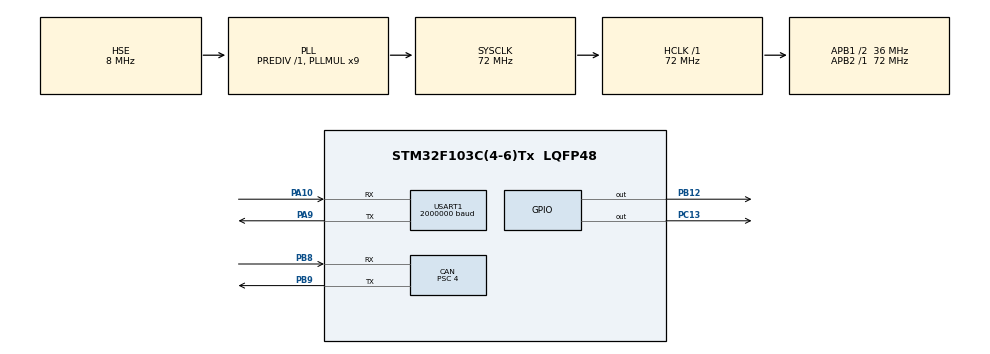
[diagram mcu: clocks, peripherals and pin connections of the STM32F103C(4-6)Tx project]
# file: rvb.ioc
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CAN.ABOM=ENABLE
CAN.AWUM=ENABLE
CAN.BS1=CAN_BS1_9TQ
CAN.BS2=CAN_BS2_8TQ
CAN.CalculateBaudRate=500000
CAN.CalculateTimeBit=2000
CAN.CalculateTimeQuantum=111.11111111111111
CAN.Mode=CAN_MODE_NORMAL
CAN.NART=DISABLE
CAN.Prescaler=4
CAN.RFLM=DISABLE
CAN.SJW=CAN_SJW_4TQ
CAN.TTCM=ENABLE
CAN.TXFP=DISABLE
FREERTOS.Queues01=QueueIO,8,sMessageType,0,Dynamic,NULL,NULL;QueueAppCAN,16,sMessageType,0,Dynamic,NULL,NULL;QueueAppSerial,16,sMessageType,0,Dynamic,NULL,NULL
FREERTOS.Tasks01=TaskIO,-3,128,TaskIO_Init,Default,NULL,Dynamic,NULL,NULL;TaskAppCAN,-3,128,TaskAppCAN_Init,Default,NULL,Dynamic,NULL,NULL;TaskAppSerial,-3,128,TaskAppSerial_Init,Default,NULL,Dynamic,NULL,NULL
FREERTOS.Timers01=TimerIO,vTimerCallbackIo,osTimerPeriodic,Default,NULL,Dynamic,NULL
FREERTOS.configUSE_NEWLIB_REENTRANT=1
FREERTOS.configUSE_TIMERS=1
FREERTOS.copyHeapFile=0
Mcu.Family=STM32F1
Mcu.Name=STM32F103C(4-6)Tx
Mcu.Package=LQFP48
NVIC.PriorityGroup=NVIC_PRIORITYGROUP_4
PA10.Mode=Asynchronous
PA10.Signal=USART1_RX
PA13.Mode=Serial_Wire
PA13.Signal=SYS_JTMS-SWDIO
PA14.Mode=Serial_Wire
PA14.Signal=SYS_JTCK-SWCLK
PA9.Mode=Asynchronous
PA9.Signal=USART1_TX
PB12.Signal=GPIO_Output
PB8.GPIO_Mode=GPIO_MODE_INPUT
PB8.GPIO_PuPd=GPIO_NOPULL
PB8.Mode=CAN_Activate
PB8.Signal=CAN_RX
PB9.Mode=CAN_Activate
PB9.Signal=CAN_TX
PC13-TAMPER-RTC.Signal=GPIO_Output
PD0-OSC_IN.Mode=HSE-External-Oscillator
PD0-OSC_IN.Signal=RCC_OSC_IN
PD1-OSC_OUT.Mode=HSE-External-Oscillator
PD1-OSC_OUT.Signal=RCC_OSC_OUT
ProjectManager.HeapSize=0x200
ProjectManager.StackSize=0x400
ProjectManager.TargetToolchain=STM32CubeIDE
RCC.AHBFreq_Value=72000000
RCC.APB1CLKDivider=RCC_HCLK_DIV2
RCC.APB1Freq_Value=36000000
RCC.APB1TimFreq_Value=72000000
RCC.APB2Freq_Value=72000000
RCC.APB2TimFreq_Value=72000000
RCC.HCLKFreq_Value=72000000
RCC.PLLMUL=RCC_PLL_MUL9
RCC.PLLSourceVirtual=RCC_PLLSOURCE_HSE
RCC.SYSCLKFreq_VALUE=72000000
RCC.SYSCLKSource=RCC_SYSCLKSOURCE_PLLCLK
RCC.USBFreq_Value=72000000
USART1.BaudRate=2000000
USART1.VirtualMode=VM_ASYNC
VP_FREERTOS_VS_CMSIS_V1.Mode=CMSIS_V1
board=custom

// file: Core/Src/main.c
/* USER CODE BEGIN Header */
/**
  ******************************************************************************
  * @file           : main.c
  * @brief          : Main program body
  ******************************************************************************
  * @attention
  *
  * Copyright (c) 2024 STMicroelectronics.
  * All rights reserved.
  *
  * This software is licensed under terms that can be found in the LICENSE file
  * in the root directory of this software component.
  * If no LICENSE file comes with this software, it is provided AS-IS.
  *
  ******************************************************************************
  */
/* USER CODE END Header */
#include "main.h"
#include "cmsis_os.h"
#include "can.h"
#include "usart.h"
#include "gpio.h"

void SystemClock_Config(void);
void MX_FREERTOS_Init(void);

int main(void)
{

  /* MCU Configuration--------------------------------------------------------*/

  /* Reset of all peripherals, Initializes the Flash interface and the Systick. */
  HAL_Init();

  /* Configure the system clock */
  SystemClock_Config();

  /* Initialize all configured peripherals */
  MX_GPIO_Init();
  MX_CAN_Init();
  MX_USART1_UART_Init();

  /* Call init function for freertos objects (in cmsis_os2.c) */
  MX_FREERTOS_Init();

  /* Start scheduler */
  osKernelStart();

  /* We should never get here as control is now taken by the scheduler */

  /* Infinite loop */
  while (1)
  {

  }
}

void SystemClock_Config(void)
{
  RCC_OscInitTypeDef RCC_OscInitStruct = {0};
  RCC_ClkInitTypeDef RCC_ClkInitStruct = {0};

  /** Initializes the RCC Oscillators according to the specified parameters
  * in the RCC_OscInitTypeDef structure.
  */
  RCC_OscInitStruct.OscillatorType = RCC_OSCILLATORTYPE_HSE;
  RCC_OscInitStruct.HSEState = RCC_HSE_ON;
  RCC_OscInitStruct.HSEPredivValue = RCC_HSE_PREDIV_DIV1;
  RCC_OscInitStruct.HSIState = RCC_HSI_ON;
  RCC_OscInitStruct.PLL.PLLState = RCC_PLL_ON;
  RCC_OscInitStruct.PLL.PLLSource = RCC_PLLSOURCE_HSE;
  RCC_OscInitStruct.PLL.PLLMUL = RCC_PLL_MUL9;
  if (HAL_RCC_OscConfig(&RCC_OscInitStruct) != HAL_OK)
  {
    Error_Handler();
  }

  /** Initializes the CPU, AHB and APB buses clocks
  */
  RCC_ClkInitStruct.ClockType = RCC_CLOCKTYPE_HCLK|RCC_CLOCKTYPE_SYSCLK
                              |RCC_CLOCKTYPE_PCLK1|RCC_CLOCKTYPE_PCLK2;
  RCC_ClkInitStruct.SYSCLKSource = RCC_SYSCLKSOURCE_PLLCLK;
  RCC_ClkInitStruct.AHBCLKDivider = RCC_SYSCLK_DIV1;
  RCC_ClkInitStruct.APB1CLKDivider = RCC_HCLK_DIV2;
  RCC_ClkInitStruct.APB2CLKDivider = RCC_HCLK_DIV1;

  if (HAL_RCC_ClockConfig(&RCC_ClkInitStruct, FLASH_LATENCY_2) != HAL_OK)
  {
    Error_Handler();
  }
}

void Error_Handler(void)
{
  __disable_irq();
  while (1)
  {
  }
}

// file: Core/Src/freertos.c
/* USER CODE BEGIN Header */
/**
  ******************************************************************************
  * File Name          : freertos.c
  * Description        : Code for freertos applications
  ******************************************************************************
  * @attention
  *
  * Copyright (c) 2024 STMicroelectronics.
  * All rights reserved.
  *
  * This software is licensed under terms that can be found in the LICENSE file
  * in the root directory of this software component.
  * If no LICENSE file comes with this software, it is provided AS-IS.
  *
  ******************************************************************************
  */
/* USER CODE END Header */

#include "FreeRTOS.h"
#include "task.h"
#include "main.h"
#include "cmsis_os.h"

/* USER CODE BEGIN Includes */
#include "defines.h"
#include "TaskIO.h"
#include "TaskAppCAN.h"
#include "TaskAppSerial.h"
/* USER CODE END Includes */

osThreadId TaskIOHandle;
osThreadId TaskAppCANHandle;
osThreadId TaskAppSerialHandle;
osMessageQId QueueIOHandle;
osMessageQId QueueAppCANHandle;
osMessageQId QueueAppSerialHandle;
osTimerId TimerIOHandle;

void TaskIO_Init(void const * argument);
void TaskAppCAN_Init(void const * argument);
void TaskAppSerial_Init(void const * argument);
void vTimerCallbackIo(void const * argument);

void MX_FREERTOS_Init(void); /* (MISRA C 2004 rule 8.1) */

/* GetIdleTaskMemory prototype (linked to static allocation support) */
void vApplicationGetIdleTaskMemory( StaticTask_t **ppxIdleTaskTCBBuffer, StackType_t **ppxIdleTaskStackBuffer, uint32_t *pulIdleTaskStackSize );

/* GetTimerTaskMemory prototype (linked to static allocation support) */
void vApplicationGetTimerTaskMemory( StaticTask_t **ppxTimerTaskTCBBuffer, StackType_t **ppxTimerTaskStackBuffer, uint32_t *pulTimerTaskStackSize );

/* USER CODE BEGIN GET_IDLE_TASK_MEMORY */
static StaticTask_t xIdleTaskTCBBuffer;
static StackType_t xIdleStack[configMINIMAL_STACK_SIZE];

void vApplicationGetIdleTaskMemory( StaticTask_t **ppxIdleTaskTCBBuffer, StackType_t **ppxIdleTaskStackBuffer, uint32_t *pulIdleTaskStackSize )
{
  *ppxIdleTaskTCBBuffer = &xIdleTaskTCBBuffer;
  *ppxIdleTaskStackBuffer = &xIdleStack[0];
  *pulIdleTaskStackSize = configMINIMAL_STACK_SIZE;
  /* place for user code */
}
/* USER CODE END GET_IDLE_TASK_MEMORY */

/* USER CODE BEGIN GET_TIMER_TASK_MEMORY */
static StaticTask_t xTimerTaskTCBBuffer;
static StackType_t xTimerStack[configTIMER_TASK_STACK_DEPTH];

void vApplicationGetTimerTaskMemory( StaticTask_t **ppxTimerTaskTCBBuffer, StackType_t **ppxTimerTaskStackBuffer, uint32_t *pulTimerTaskStackSize )
{
  *ppxTimerTaskTCBBuffer = &xTimerTaskTCBBuffer;
  *ppxTimerTaskStackBuffer = &xTimerStack[0];
  *pulTimerTaskStackSize = configTIMER_TASK_STACK_DEPTH;
  /* place for user code */
}
/* USER CODE END GET_TIMER_TASK_MEMORY */

void MX_FREERTOS_Init(void) {

  /* Create the timer(s) */
  /* definition and creation of TimerIO */
  osTimerDef(TimerIO, vTimerCallbackIo);
  TimerIOHandle = osTimerCreate(osTimer(TimerIO), osTimerPeriodic, NULL);

  /* Create the queue(s) */
  /* definition and creation of QueueIO */
  osMessageQDef(QueueIO, 8, sMessageType);
  QueueIOHandle = osMessageCreate(osMessageQ(QueueIO), NULL);

  /* definition and creation of QueueAppCAN */
  osMessageQDef(QueueAppCAN, 16, sMessageType);
  QueueAppCANHandle = osMessageCreate(osMessageQ(QueueAppCAN), NULL);

  /* definition and creation of QueueAppSerial */
  osMessageQDef(QueueAppSerial, 16, sMessageType);
  QueueAppSerialHandle = osMessageCreate(osMessageQ(QueueAppSerial), NULL);

  /* Create the thread(s) */
  /* definition and creation of TaskIO */
  osThreadDef(TaskIO, TaskIO_Init, osPriorityIdle, 0, 128);
  TaskIOHandle = osThreadCreate(osThread(TaskIO), NULL);

  /* definition and creation of TaskAppCAN */
  osThreadDef(TaskAppCAN, TaskAppCAN_Init, osPriorityIdle, 0, 128);
  TaskAppCANHandle = osThreadCreate(osThread(TaskAppCAN), NULL);

  /* definition and creation of TaskAppSerial */
  osThreadDef(TaskAppSerial, TaskAppSerial_Init, osPriorityIdle, 0, 128);
  TaskAppSerialHandle = osThreadCreate(osThread(TaskAppSerial), NULL);

}

void TaskIO_Init(void const * argument)
{
  /* USER CODE BEGIN TaskIO_Init */
  /* Infinite loop */
  TaskIO_Entry(QueueIOHandle,TimerIOHandle);
  for(;;)
  {
    osDelay(50);
    vTaskIO(argument);
  }
  /* USER CODE END TaskIO_Init */
}

void TaskAppCAN_Init(void const * argument)
{
  /* USER CODE BEGIN TaskAppCAN_Init */
  /* Infinite loop */
  TaskAppCAN_Entry(QueueAppCANHandle,NULL);
  for(;;)
  {
    osDelay(1);
    vTaskAppCAN(argument);
  }
  /* USER CODE END TaskAppCAN_Init */
}

void TaskAppSerial_Init(void const * argument)
{
  /* USER CODE BEGIN TaskAppSerial_Init */
  /* Infinite loop */
  TaskAppSerial_Entry(QueueAppSerialHandle,NULL);
  for(;;)
  {
    osDelay(1);
    vTaskAppSerial(argument);
  }
  /* USER CODE END TaskAppSerial_Init */
}

/* vTimerCallbackIo function */
void vTimerCallbackIo(void const * argument)
{
  /* USER CODE BEGIN vTimerCallbackIo */
	vLocalTimerCallbackIo(argument);
  /* USER CODE END vTimerCallbackIo */
}
